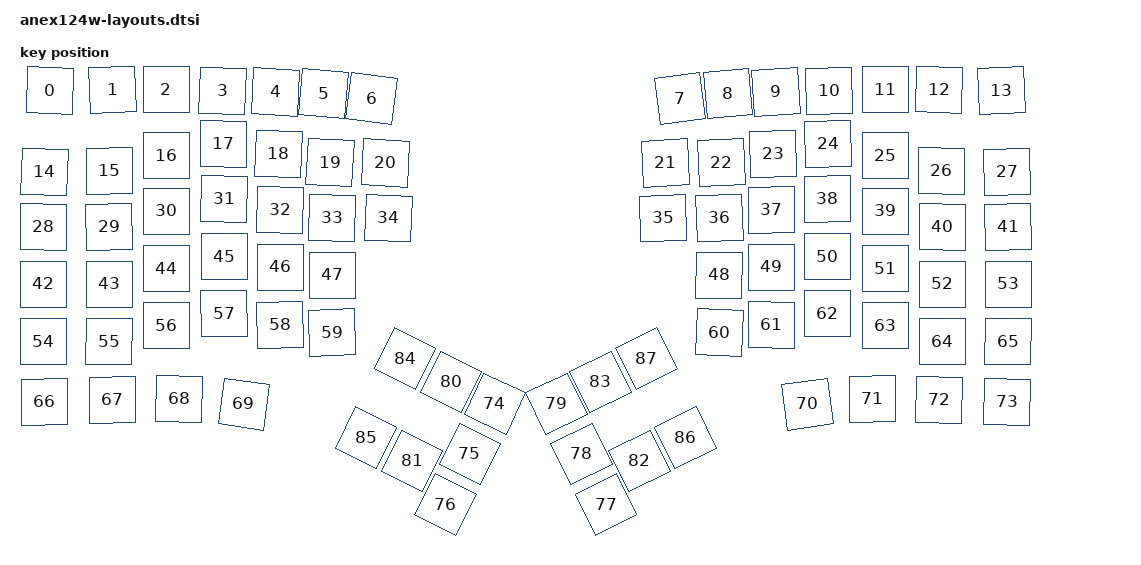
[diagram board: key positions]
#include <physical_layouts.dtsi>

/ {
    default_layout: physical_layout_0 {
        compatible = "zmk,physical-layout";
        display-name = "Default Layout";
        transform = <&default_transform>;

        keys
            = <&key_physical_attrs 100 100 14 2 198 64 52>
            , <&key_physical_attrs 100 100 139 0 (-155) 189 50>
            , <&key_physical_attrs 100 100 246 0 0 0 0>
            , <&key_physical_attrs 100 100 359 3 155 409 53>
            , <&key_physical_attrs 100 100 465 5 318 515 55>
            , <&key_physical_attrs 100 100 561 8 499 611 58>
            , <&key_physical_attrs 100 100 657 18 712 707 68>
            , <&key_physical_attrs 100 100 1274 18 (-712) 1324 68>
            , <&key_physical_attrs 100 100 1370 8 (-499) 1420 58>
            , <&key_physical_attrs 100 100 1466 5 (-318) 1516 55>
            , <&key_physical_attrs 100 100 1572 3 (-155) 1622 53>
            , <&key_physical_attrs 100 100 1685 0 0 0 0>
            , <&key_physical_attrs 100 100 1792 0 155 1842 50>
            , <&key_physical_attrs 100 100 1917 2 (-198) 1967 52>
            , <&key_physical_attrs 100 100 3 164 138 53 214>
            , <&key_physical_attrs 100 100 133 163 (-103) 183 213>
            , <&key_physical_attrs 100 100 246 132 0 0 0>
            , <&key_physical_attrs 100 100 361 108 103 411 158>
            , <&key_physical_attrs 100 100 471 129 212 521 179>
            , <&key_physical_attrs 100 100 574 146 334 624 196>
            , <&key_physical_attrs 100 100 685 147 322 735 197>
            , <&key_physical_attrs 100 100 1245 147 (-322) 1295 197>
            , <&key_physical_attrs 100 100 1357 146 (-334) 1407 196>
            , <&key_physical_attrs 100 100 1460 129 (-212) 1510 179>
            , <&key_physical_attrs 100 100 1570 108 (-103) 1620 158>
            , <&key_physical_attrs 100 100 1685 132 0 0 0>
            , <&key_physical_attrs 100 100 1797 163 103 1847 213>
            , <&key_physical_attrs 100 100 1928 164 (-138) 1978 214>
            , <&key_physical_attrs 100 100 1 275 72 51 325>
            , <&key_physical_attrs 100 100 132 275 (-52) 182 325>
            , <&key_physical_attrs 100 100 246 243 0 0 0>
            , <&key_physical_attrs 100 100 362 219 52 412 269>
            , <&key_physical_attrs 100 100 474 240 106 524 290>
            , <&key_physical_attrs 100 100 578 257 168 628 307>
            , <&key_physical_attrs 100 100 691 257 218 741 307>
            , <&key_physical_attrs 100 100 1240 257 (-218) 1290 307>
            , <&key_physical_attrs 100 100 1353 257 (-168) 1403 307>
            , <&key_physical_attrs 100 100 1457 240 (-106) 1507 290>
            , <&key_physical_attrs 100 100 1569 219 (-52) 1619 269>
            , <&key_physical_attrs 100 100 1685 243 0 0 0>
            , <&key_physical_attrs 100 100 1799 275 52 1849 325>
            , <&key_physical_attrs 100 100 1930 275 (-72) 1980 325>
            , <&key_physical_attrs 100 100 0 389 0 0 0>
            , <&key_physical_attrs 100 100 132 389 0 0 0>
            , <&key_physical_attrs 100 100 246 358 0 0 0>
            , <&key_physical_attrs 100 100 363 334 0 0 0>
            , <&key_physical_attrs 100 100 474 355 0 0 0>
            , <&key_physical_attrs 100 100 579 371 (-5) 629 421>
            , <&key_physical_attrs 100 100 1352 371 5 1402 421>
            , <&key_physical_attrs 100 100 1457 355 0 0 0>
            , <&key_physical_attrs 100 100 1568 334 0 0 0>
            , <&key_physical_attrs 100 100 1685 358 0 0 0>
            , <&key_physical_attrs 100 100 1799 389 0 0 0>
            , <&key_physical_attrs 100 100 1931 389 0 0 0>
            , <&key_physical_attrs 100 100 1 504 (-72) 51 554>
            , <&key_physical_attrs 100 100 132 504 52 182 554>
            , <&key_physical_attrs 100 100 246 472 0 0 0>
            , <&key_physical_attrs 100 100 362 448 (-52) 412 498>
            , <&key_physical_attrs 100 100 474 470 (-106) 524 520>
            , <&key_physical_attrs 100 100 578 486 (-168) 628 536>
            , <&key_physical_attrs 100 100 1353 486 168 1403 536>
            , <&key_physical_attrs 100 100 1457 470 106 1507 520>
            , <&key_physical_attrs 100 100 1569 448 52 1619 498>
            , <&key_physical_attrs 100 100 1685 472 0 0 0>
            , <&key_physical_attrs 100 100 1799 504 (-52) 1849 554>
            , <&key_physical_attrs 100 100 1930 504 72 1980 554>
            , <&key_physical_attrs 100 100 3 625 (-34) 53 675>
            , <&key_physical_attrs 100 100 139 620 (-103) 189 670>
            , <&key_physical_attrs 100 100 272 619 94 322 669>
            , <&key_physical_attrs 100 100 402 629 791 452 679>
            , <&key_physical_attrs 100 100 1529 629 (-791) 1579 679>
            , <&key_physical_attrs 100 100 1659 619 (-94) 1709 669>
            , <&key_physical_attrs 100 100 1792 620 103 1842 670>
            , <&key_physical_attrs 100 100 1928 625 34 1978 675>
            , <&key_physical_attrs 100 100 904 628 11500 954 678>
            , <&key_physical_attrs 100 100 854 729 11574 904 779>
            , <&key_physical_attrs 100 100 805 830 11650 855 880>
            , <&key_physical_attrs 100 100 1126 830 (-11650) 1176 880>
            , <&key_physical_attrs 100 100 1077 729 (-11574) 1127 779>
            , <&key_physical_attrs 100 100 1027 628 (-11500) 1077 678>
            , <&key_physical_attrs 100 100 816 585 11574 866 635>
            , <&key_physical_attrs 100 100 738 743 11612 788 793>
            , <&key_physical_attrs 100 100 1193 743 (-11612) 1243 793>
            , <&key_physical_attrs 100 100 1115 585 (-11574) 1165 635>
            , <&key_physical_attrs 100 100 724 538 2699 774 588>
            , <&key_physical_attrs 100 100 646 696 11612 696 746>
            , <&key_physical_attrs 100 100 1285 696 (-11612) 1335 746>
            , <&key_physical_attrs 100 100 1207 538 (-2699) 1257 588>
            ;
    };
};
